# R7FA8D1BH register map
Vendor: Renesas; Series: RA8; File version: 1.2
CPU: CM85 r0p0, little endian, MPU, FPU, VTOR, 4 interrupt priority bits
Registers are 32-bit, read-write, reset 0x0 unless marked. A register's access mark holds for its fields unless they carry their own. Offsets are from the block's base; [hi:lo] are bit positions; {n}, {i} and the like mark numbered series.

## GPT_OPS — Output Phase Switching Controller
Base 0x40323F00
Same registers: GPT_OPS_NS 0x50323F00
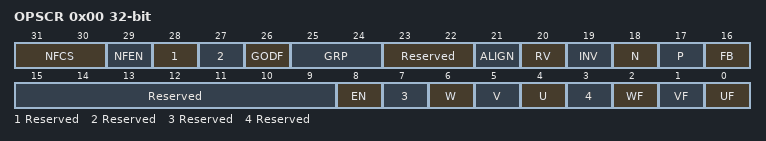
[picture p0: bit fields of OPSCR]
0x00 OPSCR — Output Phase Switching Control Register
  [31:30] NFCS — External Input Noise Filter Clock selectionNoise filter sampling clock setting of the external input.
    0=PCLKGPT0/1; 1=PCLKGPT0/4; 2=PCLKGPT0/16; 3=PCLKGPT0/64
  [29] NFEN — External Input Noise Filter Enable
    0=Do not use a noise filter to the external input; 1=Use a noise filter to the external input
  [28] Reserved — This bit is read as 0. The write value should be 0.
  [27] Reserved — This bit is read as 0. The write value should be 0.
  [26] GODF — Group output disable function
    0=This bit function is ignored; 1=Group disable will clear OPSCR.EN Bit
  [25:24] GRP — Output disabled source selection
    0=Select Group A output disable source; 1=Select Group B output disable source; 2=Select Group C output disable source; 3=Select Group D output disable source
  [23:22] Reserved — These bits are read as 00. The write value should be 00.
  [21] ALIGN — Input phase alignment
    0=Input phase is aligned to PCLK; 1=Input phase is aligned PWM
  [20] RV — Output phase rotation direction reversal
  [19] INV — Invert-Phase Output Control
    0=Positive Logic (Active High)output; 1=Negative Logic (Active Low)output
  [18] N — Negative-Phase Output (N) Control
    0=Level signal output; 1=PWM signal output (PWM of GPT0)
  [17] P — Positive-Phase Output (P) Control
    0=Level signal output; 1=PWM signal output (PWM of GPT0)
  [16] FB — External Feedback Signal EnableThis bit selects the input phase from the software settings and external input.
    0=Select the external input; 1=Select the soft setting(OPSCR.UF, VF, WF)
  [15:9] Reserved — These bits are read as 0000000. The write value should be 0000000.
  [8] EN — Enable-Phase Output Control
    0=Not Output(Hi-Z external terminals); 1=Output
  [7] Reserved — This bit is read as 0. The write value should be 0.
  [6] W ro — Input W-Phase MonitorThis bit monitors the state of the input phase.OPSCR.FB=0:External input monitoring by PCLKGPT0OPSCR.FB=1:Software settings (UF/VF/WF)
  [5] V ro — Input V-Phase MonitorThis bit monitors the state of the input phase.OPSCR.FB=0:External input monitoring by PCLKGPT0OPSCR.FB=1:Software settings (UF/VF/WF)
  [4] U ro — Input U-Phase MonitorThis bit monitors the state of the input phase.OPSCR.FB=0:External input monitoring by PCLKGPT0OPSCR.FB=1:Software settings (UF/VF/WF)
  [3] Reserved — This bit is read as 0. The write value should be 0.
  [2] WF — Input Phase Soft Setting WFThis bit sets the input phase by the software settings.This bit setting is valid when the OPSCR.FB bit = 1.
  [1] VF — Input Phase Soft Setting VFThis bit sets the input phase by the software settings.This bit setting is valid when the OPSCR.FB bit = 1.
  [0] UF — Input Phase Soft Setting UFThis bit sets the input phase by the software settings.This bit setting is valid when the OPSCR.FB bit = 1.

## DAC12 — 12-bit D/A converter
Base 0x40333000
Same registers: DAC12_NS 0x50333000
{0x0+2i} DADR{i} (i=0..1) 16-bit — D/A Data Register {i}
  [15:0] DADR — D/A Data RegisterNOTE: When DADPR.DPSEL = 0, the high-order 4 bits are fixed to 0: right justified format. When DADPR.DPSEL = 1, the low-order 4 bits are fixed to 0: left justified format.
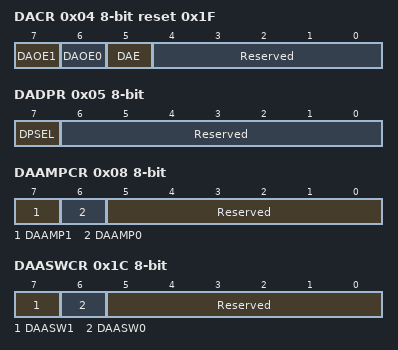
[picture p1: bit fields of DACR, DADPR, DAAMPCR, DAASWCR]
0x04 DACR 8-bit reset 0x1F — D/A Control Register
  [7] DAOE1 — D/A Output Enable 1
    0=Analog output of channel 1 (DA1) is disabled; 1=D/A conversion of channel 1 is enabled. Analog output of channel 1 (DA1) is enabled.
  [6] DAOE0 — D/A Output Enable 0
    0=Analog output of channel 0 (DA0) is disabled; 1=D/A conversion of channel 0 is enabled. Analog output of channel 0 (DA0) is enabled.
  [5] DAE — D/A Enable
    0=D/A conversion is independently controlled on channels 0 and 1; 1=D/A conversion on channels 0 and 1 is controlled as a single whole
  [4:0] Reserved — These bits are read as 11111. The write value should be 11111.
0x05 DADPR 8-bit — DADRm Format Select Register
  [7] DPSEL — DADRm Format Select
    0=Right justified format; 1=Left justified format
  [6:0] Reserved — These bits are read as 0000000. The write value should be 0000000.
0x06 DAADSCR 8-bit — D/A-A/D Synchronous Start Control Register
  [7] DAADST — D/A-A/D Synchronous Conversion
    0=D/A converter operation does not synchronize with A/D converter operation (unit 1) (countermeasure against interference between D/A and A/D conversions is disabled); 1=D/A converter operation synchronizes with A/D converter operation (unit 1) (countermeasure against interference between D/A and A/D conversions is enabled)
0x08 DAAMPCR 8-bit — D/A Output Amplifier Control Register
  [7] DAAMP1 — Amplifier Control 1
    0=Output amplifier of channel 1 is not used; 1=Output amplifier of channel 1 is used
  [6] DAAMP0 — Amplifier Control 0
    0=Output amplifier of channel 0 is not used; 1=Output amplifier of channel 0 is used
  [5:0] Reserved — These bits are read as 000000. The write value should be 000000.
0x1C DAASWCR 8-bit — D/A Amplifier Stabilization Wait Control Register
  [7] DAASW1 — D/A Amplifier Stabilization Wait 1
    0=Amplifier stabilization wait off (output) for channel 1; 1=Amplifier stabilization wait on (high-Z) for channel 1
  [6] DAASW0 — D/A Amplifier Stabilization Wait 0
    0=Amplifier stabilization wait off (output) for channel 0; 1=Amplifier stabilization wait on (high-Z) for channel 0
  [5:0] Reserved — These bits are read as 000000. The write value should be 000000.
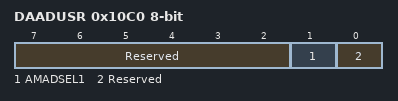
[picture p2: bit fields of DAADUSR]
0x10C0 DAADUSR 8-bit — D/A A/D Synchronous Unit Select Register
  [7:2] Reserved — These bits are read as 000000. The write value should be 000000.
  [1] AMADSEL1 — A/D Unit 1 Select
    0=Unit 1 is not selected; 1=Unit 1 is selected
  [0] Reserved — This bit is read as 0. The write value should be 0.
